# M369 register map
File version: 0.1
CPU: 
Registers are 32-bit, read-write, reset 0x0 unless marked. A register's access mark holds for its fields unless they carry their own. Offsets are from the block's base; [hi:lo] are bit positions; {n}, {i} and the like mark numbered series.

## SBI0 — Serial Bus Interface (SBI)
Base 0x400E0000
Same registers: SBI1 0x400E0100, SBI2 0x400E0200
0x00 CR0 — SBI Control Register 0
  [7] SBIEN
0x04 CR1_A reset 0x3 — SBI Control Register 1 (I2C Mode)
  [7:5] BC, [4] ACK, [0] SWRMON ro, [2:0] SCK wo
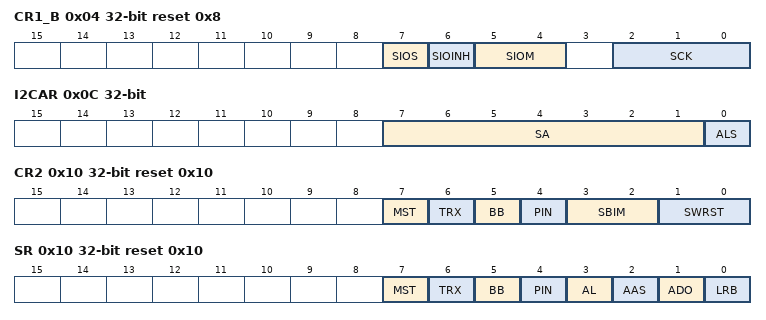
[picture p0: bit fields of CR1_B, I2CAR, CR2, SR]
0x04 CR1_B reset 0x8 (SBI_CR1 view) — SBI Control Register 1 (SIO Mode)
  [7] SIOS, [6] SIOINH, [5:4] SIOM, [2:0] SCK
0x08 DBR — SBI Data Buffer Register
  [7:0] DB
0x0C I2CAR — SBI I2C Bus Address Register
  [7:1] SA, [0] ALS
0x10 CR2 wo reset 0x10 — SBI Control Register 2 (I2C Mode)
  [7] MST, [6] TRX, [5] BB, [4] PIN, [3:2] SBIM, [1:0] SWRST
0x10 SR ro reset 0x10 — SBI Status Register (I2C Mode)
  [7] MST, [6] TRX, [5] BB, [4] PIN, [3] AL, [2] AAS, [1] ADO, [0] LRB
0x14 BR0 reset 0xBE — SBI Baud Rate Register 0
  [6] I2SBI

## SC0 — Serial Channel (SC)
Base 0x400E1000
Same registers: SC1 0x400E1100, SC2 0x400E1200, SC3 0x400E1300
0x00 EN — SC Enable Register
  [0] SIOE
0x04 BUF — SC Buffer Register
  [7:0] TB_RB
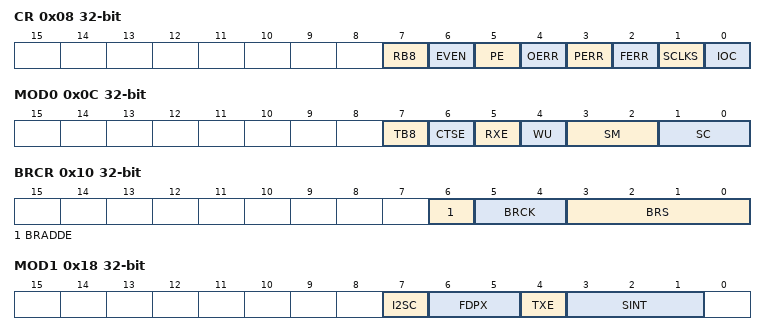
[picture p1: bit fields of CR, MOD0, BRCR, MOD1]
0x08 CR — SC Control Register
  [7] RB8 ro, [6] EVEN, [5] PE, [4] OERR ro, [3] PERR ro, [2] FERR ro, [1] SCLKS, [0] IOC
0x0C MOD0 — SC Mode Control Register 0
  [7] TB8, [6] CTSE, [5] RXE, [4] WU, [3:2] SM, [1:0] SC
0x10 BRCR — SC Baud Rate Generator Control Register
  [6] BRADDE, [5:4] BRCK, [3:0] BRS
0x14 BRADD — SC Baud Rate Generator Control Register 2
  [3:0] BRK
0x18 MOD1 — SC Mode Control Register 1
  [7] I2SC, [6:5] FDPX, [4] TXE, [3:1] SINT
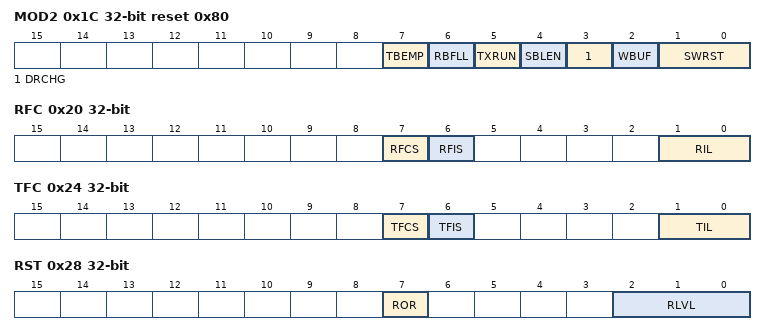
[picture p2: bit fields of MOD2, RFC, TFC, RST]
0x1C MOD2 reset 0x80 — SC Mode Control Register 2
  [7] TBEMP ro, [6] RBFLL ro, [5] TXRUN ro, [4] SBLEN, [3] DRCHG, [2] WBUF, [1:0] SWRST
0x20 RFC — SC RX FIFO Configuration Register
  [7] RFCS wo, [6] RFIS, [1:0] RIL
0x24 TFC — SC TX FIFO Configuration Register
  [7] TFCS wo, [6] TFIS, [1:0] TIL
0x28 RST ro — SC RX FIFO Status Register
  [7] ROR, [2:0] RLVL
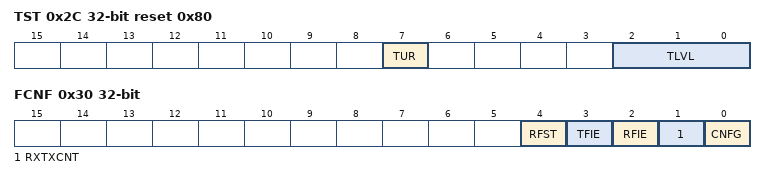
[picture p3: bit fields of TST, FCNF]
0x2C TST ro reset 0x80 — SC TX FIFO Status Register
  [7] TUR, [2:0] TLVL
0x30 FCNF — SC FIFO Configuration Register
  [4] RFST, [3] TFIE, [2] RFIE, [1] RXTXCNT, [0] CNFG

## RMC — Remote Control Signal Preprocessor (RMC)
Base 0x400E7000
0x00 EN — RMC Enable Register
  [0] RMCEN
0x04 REN — RMC Receive Enable Register
  [0] RMCREN
0x08 RBUF1 ro — RMC Receive Data Buffer Register 1
  [31:0] RMCRBUF
0x0C RBUF2 ro — RMC Receive Data Buffer Register 2
  [31:0] RMCRBUF
0x10 RBUF3 ro — RMC Receive Data Buffer Register 3
  [7:0] RMCRBUF
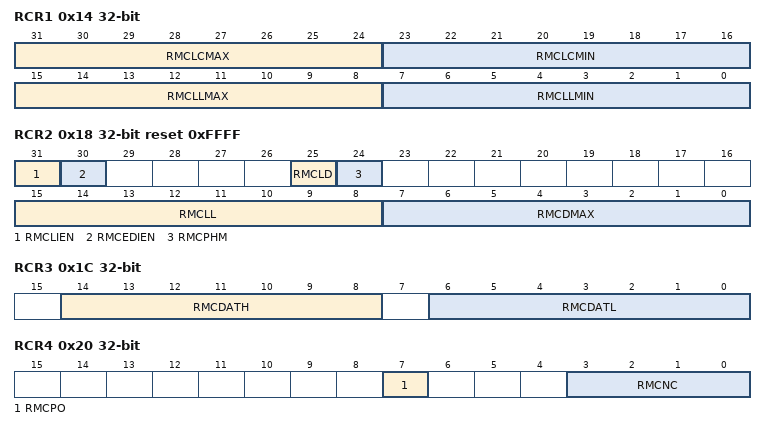
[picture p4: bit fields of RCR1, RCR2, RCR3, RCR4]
0x14 RCR1 — RMC Receive Control Register 1
  [31:24] RMCLCMAX, [23:16] RMCLCMIN, [15:8] RMCLLMAX, [7:0] RMCLLMIN
0x18 RCR2 reset 0xFFFF — RMC Receive Control Register 2
  [31] RMCLIEN, [30] RMCEDIEN, [25] RMCLD, [24] RMCPHM, [15:8] RMCLL, [7:0] RMCDMAX
0x1C RCR3 — RMC Receive Control Register 3
  [14:8] RMCDATH, [6:0] RMCDATL
0x20 RCR4 — RMC Receive Control Register 4
  [7] RMCPO, [3:0] RMCNC
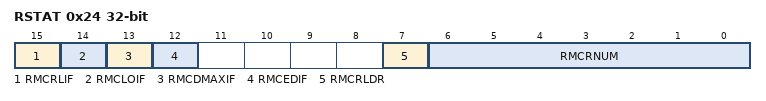
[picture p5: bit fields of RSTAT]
0x24 RSTAT ro — RMC Receive Status Register
  [15] RMCRLIF, [14] RMCLOIF, [13] RMCDMAXIF, [12] RMCEDIF, [7] RMCRLDR, [6:0] RMCRNUM
{0x24+4i} END{i} (i=1..3) — RMC Receive End Bit Number Register {i}
  [6:0] RMCEND{i}
0x34 FSSEL — RMC Frequency Selection Register
  [0] RMCCLK

## OFD — Oscillation Frequency Detector (OFD)
Base 0x400F1000
0x00 CR1 reset 0x6 — OFD Control Register 1
  [7:0] OFDWEN
0x04 CR2 — OFD Control Register 2
  [7:0] OFDEN
0x08 MN0 — OFD Lower Detection Frequency Setting Register
  [8:0] OFDMN0
0x0C MN1 — OFD Lower Detection Frequency Setting Register
  [8:0] OFDMN1
0x10 MX0 — OFD Higher Detection Frequency Setting Register
  [8:0] OFDMX0
0x14 MX1 — OFD Higher Detection Frequency Setting Register
  [8:0] OFDMX1
0x18 RST reset 0x1 — OFD Reset Enable Control Register
  [0] OFDRSTEN
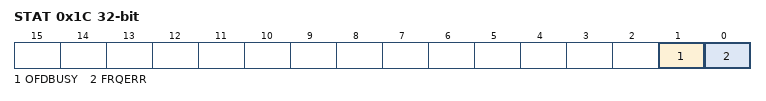
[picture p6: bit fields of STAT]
0x1C STAT ro — OFD Status Register
  [1] OFDBUSY, [0] FRQERR
0x20 MON reset 0x1 — OFD
  [0] OFDMON

## WD — Watchdog Timer (WD)
Base 0x400F2000
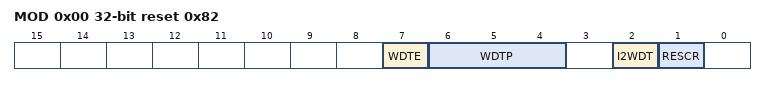
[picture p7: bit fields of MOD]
0x00 MOD reset 0x82 — WD Mode Register
  [7] WDTE, [6:4] WDTP, [2] I2WDT, [1] RESCR
0x04 CR wo (reset mask 0xFFFFFF00) — WD Control Register
